# TLSR8278 register map
File version: 0.1
Registers are 8-bit, access not given, no defined reset value unless marked. A register's access mark holds for its fields unless they carry their own. Offsets are from the block's base; [hi:lo] are bit positions.

## AES — Auto-generated from section 'aes'
Base 0x00800540
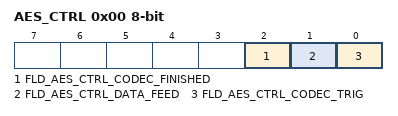
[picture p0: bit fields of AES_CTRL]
0x00 AES_CTRL — Auto-generated from aes_ctrl
  [2] FLD_AES_CTRL_CODEC_FINISHED, [1] FLD_AES_CTRL_DATA_FEED, [0] FLD_AES_CTRL_CODEC_TRIG
0x08 AES_DATA 32-bit — Auto-generated from aes_data

## AUDIO — Auto-generated from section 'audio'
Base 0x00800560
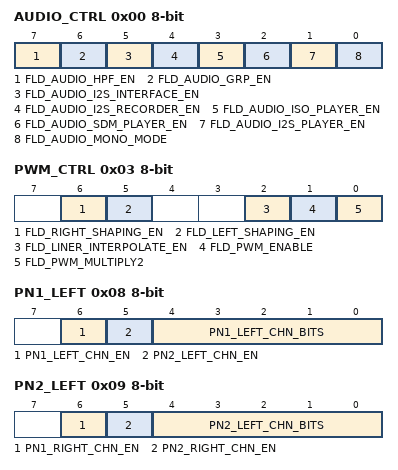
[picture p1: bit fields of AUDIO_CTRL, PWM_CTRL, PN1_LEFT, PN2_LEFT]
0x00 AUDIO_CTRL — Auto-generated from audio_ctrl
  [7] FLD_AUDIO_HPF_EN, [6] FLD_AUDIO_GRP_EN, [5] FLD_AUDIO_I2S_INTERFACE_EN, [4] FLD_AUDIO_I2S_RECORDER_EN, [3] FLD_AUDIO_ISO_PLAYER_EN, [2] FLD_AUDIO_SDM_PLAYER_EN, [1] FLD_AUDIO_I2S_PLAYER_EN, [0] FLD_AUDIO_MONO_MODE
0x03 PWM_CTRL — Auto-generated from pwm_ctrl
  [6] FLD_RIGHT_SHAPING_EN, [5] FLD_LEFT_SHAPING_EN, [2] FLD_LINER_INTERPOLATE_EN, [1] FLD_PWM_ENABLE, [0] FLD_PWM_MULTIPLY2
0x04 ASCL_TUNE 32-bit — Auto-generated from ascl_tune
0x08 PN1_LEFT — Auto-generated from pn1_left
  [6] PN1_LEFT_CHN_EN, [5] PN2_LEFT_CHN_EN, [4:0] PN1_LEFT_CHN_BITS
0x09 PN2_LEFT — Auto-generated from pn2_left
  [6] PN1_RIGHT_CHN_EN, [5] PN2_RIGHT_CHN_EN, [4:0] PN2_LEFT_CHN_BITS
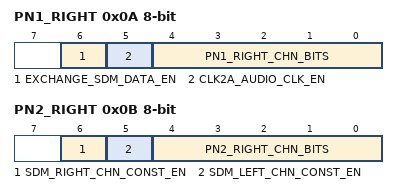
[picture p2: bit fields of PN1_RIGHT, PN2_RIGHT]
0x0A PN1_RIGHT — Auto-generated from pn1_right
  [6] EXCHANGE_SDM_DATA_EN, [5] CLK2A_AUDIO_CLK_EN, [4:0] PN1_RIGHT_CHN_BITS
0x0B PN2_RIGHT — Auto-generated from pn2_right
  [6] SDM_RIGHT_CHN_CONST_EN, [5] SDM_LEFT_CHN_CONST_EN, [4:0] PN2_RIGHT_CHN_BITS

## GPIO — Auto-generated from section 'gpio'
Base 0x00800580
0x00 GPIO_PA_IN 32-bit — Auto-generated from gpio_pa_in; aliases: GPIO_PA_SETTING1
0x01 GPIO_PA_IE — Auto-generated from gpio_pa_ie
0x02 GPIO_PA_OEN — Auto-generated from gpio_pa_oen
0x03 GPIO_PA_OUT — Auto-generated from gpio_pa_out
0x04 GPIO_PA_POL 32-bit — Auto-generated from gpio_pa_pol; aliases: GPIO_PA_SETTING2
0x05 GPIO_PA_DS — Auto-generated from gpio_pa_ds
0x06 GPIO_PA_GPIO — Auto-generated from gpio_pa_gpio
0x07 GPIO_PA_IRQ_EN — Auto-generated from gpio_pa_irq_en
0x08 GPIO_PB_IN 32-bit — Auto-generated from gpio_pb_in; aliases: GPIO_PB_SETTING1
0x09 GPIO_PB_IE — Auto-generated from gpio_pb_ie
0x0A GPIO_PB_OEN — Auto-generated from gpio_pb_oen
0x0B GPIO_PB_OUT — Auto-generated from gpio_pb_out
0x0C GPIO_PB_POL 32-bit — Auto-generated from gpio_pb_pol; aliases: GPIO_PB_SETTING2
0x0D GPIO_PB_DS — Auto-generated from gpio_pb_ds
0x0E GPIO_PB_GPIO — Auto-generated from gpio_pb_gpio
0x0F GPIO_PB_IRQ_EN — Auto-generated from gpio_pb_irq_en
0x10 GPIO_PC_IN — Auto-generated from gpio_pc_in
0x12 GPIO_PC_OEN — Auto-generated from gpio_pc_oen
0x13 GPIO_PC_OUT — Auto-generated from gpio_pc_out
0x14 GPIO_PC_POL — Auto-generated from gpio_pc_pol
0x16 GPIO_PC_GPIO — Auto-generated from gpio_pc_gpio
0x17 GPIO_PC_IRQ_EN — Auto-generated from gpio_pc_irq_en
0x18 GPIO_PD_IN 32-bit — Auto-generated from gpio_pd_in; aliases: GPIO_PD_SETTING1
0x19 GPIO_PD_IE — Auto-generated from gpio_pd_ie
0x1A GPIO_PD_OEN — Auto-generated from gpio_pd_oen
0x1B GPIO_PD_OUT — Auto-generated from gpio_pd_out
0x1C GPIO_PD_POL 32-bit — Auto-generated from gpio_pd_pol; aliases: GPIO_PD_SETTING2
0x1D GPIO_PD_DS — Auto-generated from gpio_pd_ds
0x1E GPIO_PD_GPIO — Auto-generated from gpio_pd_gpio
0x1F GPIO_PD_IRQ_EN — Auto-generated from gpio_pd_irq_en
0x20 GPIO_PE_IN — Auto-generated from gpio_pe_in
0x21 GPIO_PE_IE — Auto-generated from gpio_pe_ie
0x22 GPIO_PE_OEN — Auto-generated from gpio_pe_oen
0x23 GPIO_PE_OUT — Auto-generated from gpio_pe_out
0x24 GPIO_PE_POL — Auto-generated from gpio_pe_pol
0x25 GPIO_PE_DS — Auto-generated from gpio_pe_ds
0x26 GPIO_PE_GPIO — Auto-generated from gpio_pe_gpio
0x27 GPIO_PE_IRQ_EN — Auto-generated from gpio_pe_irq_en
0x28 MUX_FUNC_A1 — Auto-generated from mux_func_a1
0x29 MUX_FUNC_A2 — Auto-generated from mux_func_a2
0x2A MUX_FUNC_B1 — Auto-generated from mux_func_b1
0x2B MUX_FUNC_B2 — Auto-generated from mux_func_b2
0x2C MUX_FUNC_C1 — Auto-generated from mux_func_c1
0x2D MUX_FUNC_C2 — Auto-generated from mux_func_c2
0x2E MUX_FUNC_D1 — Auto-generated from mux_func_d1
0x2F MUX_FUNC_D2 — Auto-generated from mux_func_d2
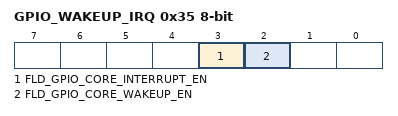
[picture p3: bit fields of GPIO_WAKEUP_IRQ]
0x35 GPIO_WAKEUP_IRQ — Auto-generated from gpio_wakeup_irq
  [3] FLD_GPIO_CORE_INTERRUPT_EN, [2] FLD_GPIO_CORE_WAKEUP_EN
0x36 PIN_I2C_SPI_OUT_EN — Auto-generated from pin_i2c_spi_out_en
  [7] FLD_PIN_PD7_I2C_EN, [7] FLD_PIN_PDGROUP_SPI_EN, [6] FLD_PIN_PB6_I2C_EN, [6] FLD_PIN_PBGROUP_SPI_EN, [5] FLD_PIN_PA4_I2C_EN, [4] FLD_PIN_PA3_I2C_EN, [5:4] FLD_PIN_PAGROUP_SPI_EN, [3] FLD_PIN_PD7_SPI_EN, [2] FLD_PIN_PB6_SPI_EN, [1] FLD_PIN_PA4_SPI_EN, [0] FLD_PIN_PA3_SPI_EN
